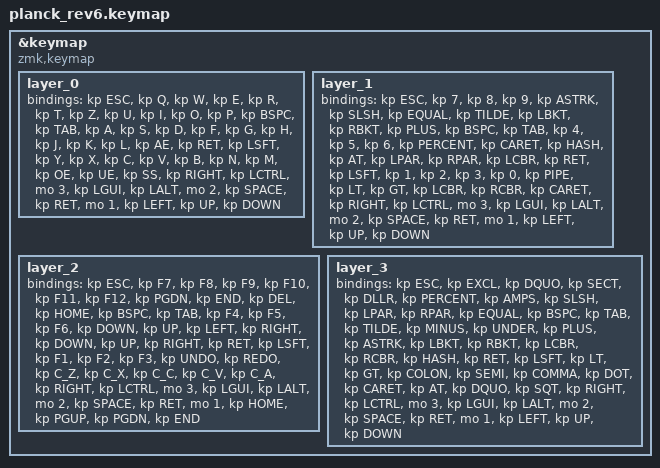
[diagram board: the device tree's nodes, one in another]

// QWERTZ Keymap mit NUM, NAV und Symbol-Layers für Plank (ZMK)

&keymap {
    compatible = "zmk,keymap";

    layer_0 {
        bindings = <
            &kp ESC     &kp Q    &kp W    &kp E    &kp R    &kp T    &kp Z    &kp U    &kp I    &kp O    &kp P    &kp BSPC
            &kp TAB     &kp A    &kp S    &kp D    &kp F    &kp G    &kp H    &kp J    &kp K    &kp L    &kp AE   &kp RET
            &kp LSFT    &kp Y    &kp X    &kp C    &kp V    &kp B    &kp N    &kp M    &kp OE   &kp UE   &kp SS   &kp RIGHT
            &kp LCTRL   &mo 3    &kp LGUI &kp LALT &mo 2    &kp SPACE &kp RET &mo 1   &kp LEFT &kp UP   &kp DOWN
        >;
    };

    layer_1 {
        bindings = <
            &kp ESC     &kp 7    &kp 8    &kp 9    &kp ASTRK &kp SLSH &kp EQUAL &kp TILDE &kp LBKT &kp RBKT &kp PLUS &kp BSPC
            &kp TAB     &kp 4    &kp 5    &kp 6    &kp PERCENT &kp CARET &kp HASH &kp AT &kp LPAR &kp RPAR &kp LCBR &kp RET
            &kp LSFT    &kp 1    &kp 2    &kp 3    &kp 0    &kp PIPE &kp LT &kp GT &kp LCBR &kp RCBR &kp CARET &kp RIGHT
            &kp LCTRL   &mo 3    &kp LGUI &kp LALT &mo 2    &kp SPACE &kp RET &mo 1   &kp LEFT &kp UP   &kp DOWN
        >;
    };

    layer_2 {
        bindings = <
            &kp ESC     &kp F7   &kp F8   &kp F9   &kp F10  &kp F11  &kp F12  &kp PGDN &kp END  &kp DEL  &kp HOME &kp BSPC
            &kp TAB     &kp F4   &kp F5   &kp F6   &kp DOWN &kp UP   &kp LEFT &kp RIGHT &kp DOWN &kp UP   &kp RIGHT &kp RET
            &kp LSFT    &kp F1   &kp F2   &kp F3   &kp UNDO &kp REDO &kp C_Z  &kp C_X  &kp C_C  &kp C_V  &kp C_A   &kp RIGHT
            &kp LCTRL   &mo 3    &kp LGUI &kp LALT &mo 2    &kp SPACE &kp RET &mo 1   &kp HOME &kp PGUP &kp PGDN &kp END
        >;
    };

    layer_3 {
        bindings = <
            &kp ESC     &kp EXCL &kp DQUO &kp SECT &kp DLLR &kp PERCENT &kp AMPS &kp SLSH &kp LPAR &kp RPAR &kp EQUAL &kp BSPC
            &kp TAB     &kp TILDE &kp MINUS &kp UNDER &kp PLUS &kp ASTRK &kp LBKT &kp RBKT &kp LCBR &kp RCBR &kp HASH &kp RET
            &kp LSFT    &kp LT   &kp GT   &kp COLON &kp SEMI &kp COMMA &kp DOT &kp CARET &kp AT &kp DQUO &kp SQT &kp RIGHT
            &kp LCTRL   &mo 3    &kp LGUI &kp LALT &mo 2    &kp SPACE &kp RET &mo 1   &kp LEFT &kp UP   &kp DOWN
        >;
    };
};
